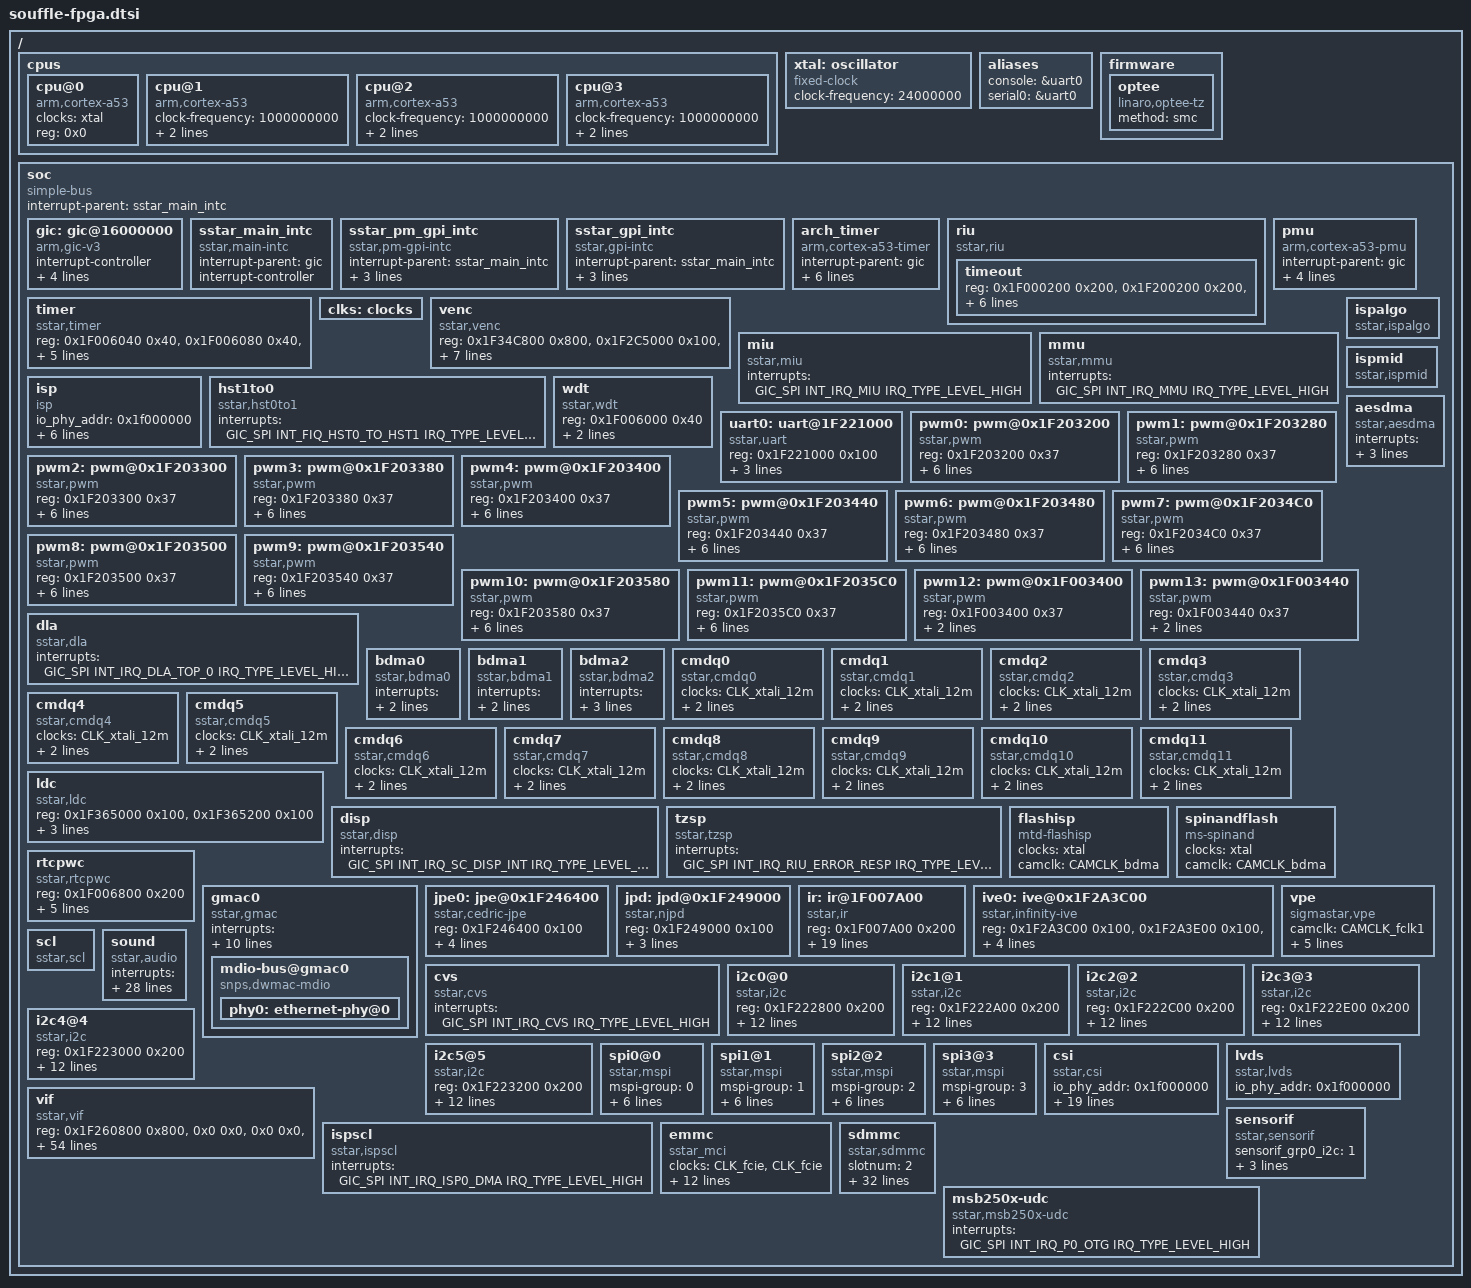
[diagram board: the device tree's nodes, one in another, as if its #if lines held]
/*
* mercury6p-fpga.dtsi- Sigmastar
*
* Copyright (c) [2019~2020] SigmaStar Technology.
*
*
* This software is licensed under the terms of the GNU General Public
* License version 2, as published by the Free Software Foundation, and
* may be copied, distributed, and modified under those terms.
*
* This program is distributed in the hope that it will be useful,
* but WITHOUT ANY WARRANTY; without even the implied warranty of
* MERCHANTABILITY or FITNESS FOR A PARTICULAR PURPOSE.  See the
* GNU General Public License version 2 for more details.
*
*/
#include "../../../../include/generated/autoconf.h"
#include "../../../../drivers/sstar/include/souffle/irqs.h"
#include "../../../../drivers/sstar/include/souffle/gpio.h"
#include <dt-bindings/interrupt-controller/irq.h>
#include <dt-bindings/interrupt-controller/arm-gic.h>
#include <dt-bindings/input/input.h>

/ {
    cpus {
        #address-cells = <1>;
        #size-cells = <0>;

        cpu@0 {
            device_type = "cpu";
            compatible = "arm,cortex-a53";
            clocks = <&xtal>;
            reg = <0x0>;
        };

#ifdef CONFIG_SMP
        cpu@1 {
            device_type = "cpu";
            compatible = "arm,cortex-a53";
            clock-frequency = <1000000000>;
            clocks = <&xtal>;
            reg = <0x1>;
        };

        cpu@2 {
            device_type = "cpu";
            compatible = "arm,cortex-a53";
            clock-frequency = <1000000000>;
            clocks = <&xtal>;
            reg = <0x2>;
        };

        cpu@3 {
            device_type = "cpu";
            compatible = "arm,cortex-a53";
            clock-frequency = <1000000000>;
            clocks = <&xtal>;
            reg = <0x3>;
        };
#endif
    };

    xtal: oscillator {
        compatible = "fixed-clock";
        #clock-cells = <0>;
        clock-frequency = <24000000>;
    };

    aliases {
        console = &uart0;
        serial0 = &uart0;
    };

#ifdef CONFIG_OPTEE
    firmware {
        optee {
            compatible = "linaro,optee-tz";
            method = "smc";
        };
    };
#endif

    soc {
        compatible = "simple-bus";
        interrupt-parent = <&sstar_main_intc>;
        #address-cells = <1>;
        #size-cells = <1>;
        ranges;

        gic: gic@16000000 {
            compatible = "arm,gic-v3";
            #interrupt-cells = <3>;
            #address-cells = <1>;
            #size-cells = <1>;
            interrupt-controller;
            interrupt-parent = <&gic>;
            redistributor-stride = <0x0 0x20000>;
            #redistributor-regions = <1>;
            reg = <0x16000000 0x20000>,
                  <0x16080000 0x80000>;
        };

        sstar_main_intc: sstar_main_intc {
            compatible = "sstar,main-intc";
            #interrupt-cells = <3>;
            #address-cells = <1>;
            #size-cells = <1>;
            interrupt-parent=<&gic>;
            interrupt-controller;
        };

        sstar_pm_gpi_intc: sstar_pm_gpi_intc {
            compatible = "sstar,pm-gpi-intc";
            #interrupt-cells = <1>;
            interrupt-parent=<&sstar_main_intc>;
            interrupt-controller;
            interrupts = <GIC_SPI INT_IRQ_PM_SLEEP IRQ_TYPE_LEVEL_HIGH>;
        };

        sstar_gpi_intc: sstar_gpi_intc {
            compatible = "sstar,gpi-intc";
            #interrupt-cells = <1>;
            interrupt-parent=<&sstar_main_intc>;
            interrupt-controller;
            interrupts = <GIC_SPI INT_IRQ_GPI_OUT IRQ_TYPE_LEVEL_HIGH>;
        };

        arch_timer {
            compatible = "arm,cortex-a53-timer", "arm,armv8-timer";
            interrupt-parent=<&gic>;
            interrupts = <GIC_PPI 13 (GIC_CPU_MASK_SIMPLE(2) | IRQ_TYPE_LEVEL_LOW)>,
                         <GIC_PPI 14 (GIC_CPU_MASK_SIMPLE(2) | IRQ_TYPE_LEVEL_LOW)>,
                         <GIC_PPI 11 (GIC_CPU_MASK_SIMPLE(2) | IRQ_TYPE_LEVEL_LOW)>,
                         <GIC_PPI 10 (GIC_CPU_MASK_SIMPLE(2) | IRQ_TYPE_LEVEL_LOW)>;
            clock-frequency = <36000000>;  /* arch_timer must use clock-frequency*/
        };

        riu {
            #address-cells = <1>;
            #size-cells = <1>;
            compatible = "sstar,riu";
            ranges;
            status = "ok";
            timeout {
                reg = <0x1F000200 0x200>, <0x1F200200 0x200>, <0x1F240200 0x200>, <0x1F2CE000 0x200>;
                interrupts= <GIC_SPI INT_FIQ_PM_XIU_TIMEOUT IRQ_TYPE_LEVEL_HIGH>, <GIC_SPI INT_FIQ_XIU_TIMEOUT IRQ_TYPE_LEVEL_HIGH>,
                            <GIC_SPI INT_FIQ_SC_XIU_TIMEOUT IRQ_TYPE_LEVEL_HIGH>, <GIC_SPI INT_FIQ_XIU_XIU_TIMEOUT IRQ_TYPE_LEVEL_HIGH>;
                //bug-on;
                status = "ok";
            };
        };

        timer {
            compatible = "sstar,timer";
            reg = <0x1F006040 0x40>, <0x1F006080 0x40>, <0x1F0060C0 0x40>;
            interrupts = <GIC_SPI INT_FIQ_TIMER_OR IRQ_TYPE_LEVEL_HIGH>, <GIC_SPI INT_FIQ_TIMER_OR IRQ_TYPE_LEVEL_HIGH>, <GIC_SPI INT_FIQ_TIMER_OR IRQ_TYPE_LEVEL_HIGH>;
            status = "ok";
        };

        pmu {
            compatible = "arm,cortex-a53-pmu";
            interrupt-parent=<&gic>;
            interrupts = <GIC_SPI 10 IRQ_TYPE_LEVEL_HIGH>,
                         <GIC_SPI 16 IRQ_TYPE_LEVEL_HIGH>,
                         <GIC_SPI 22 IRQ_TYPE_LEVEL_HIGH>,
                         <GIC_SPI 28 IRQ_TYPE_LEVEL_HIGH>;
        };

        clks: clocks{
            #address-cells = <1>;
            #size-cells = <1>;
            ranges;
        };

        venc {
            compatible = "sstar,venc";
            reg = <0x1F34C800 0x800>, <0x1F2C5000 0x100>, <0x1F203C00 0x100>, <0x1F207800 0x100>, <0x1F2C5000 0x100>;
            reg-names = "vpu-bit", "venc-brige", "hw-uart0", "hw-uart1", "venc-gp";
            interrupts = <GIC_SPI INT_IRQ_MHE_0 IRQ_TYPE_LEVEL_HIGH>;
            interrupt-parent = <&sstar_main_intc>;
            interrupt-names = "mhe-irq";
            clocks = <&CLK_vhe>, <&CLK_mfe>, <&CLK_ven_axi>,<&CLK_ven_scdn>;
            clock-names = "CKG_venc";
            status = "ok";
        };

        miu {
            compatible = "sstar,miu";
            interrupts=<GIC_SPI INT_IRQ_MIU IRQ_TYPE_LEVEL_HIGH>;
            status = "ok";
        };

        mmu {
            compatible = "sstar,mmu";
            interrupts=<GIC_SPI INT_IRQ_MMU IRQ_TYPE_LEVEL_HIGH>;
            status = "ok";
        };
        isp: isp {
            compatible = "isp";
            io_phy_addr = <0x1f000000>;
            banks = <0x1302>;
            interrupts = <GIC_SPI INT_IRQ_ISP_0 IRQ_TYPE_LEVEL_HIGH>;
            clocks = <&CLK_isp>,<&CLK_fclk1>,<&CLK_dsc_enc1>,<&CLK_dsc_dec1>;
            status = "ok";
            clock-frequency-index = <0>;
        };

        ispalgo: ispalgo {
            compatible = "sstar,ispalgo";
            status = "ok";
        };

/*
        ispscl: ispscl {
            compatible = "sstar,ispscl";
            interrupts = <GIC_SPI INT_IRQ_ISP0_DMA IRQ_TYPE_LEVEL_HIGH>;
            status = "ok";
        };
*/

        hst1to0 {
            compatible = "sstar,hst0to1";
            interrupts = <GIC_SPI INT_FIQ_HST0_TO_HST1 IRQ_TYPE_LEVEL_HIGH>;
            status = "ok";
        };

        ispmid: ispmid {
            compatible = "sstar,ispmid";
            status = "ok";
        };

        wdt {
            compatible = "sstar,wdt";
            reg = <0x1F006000 0x40>;
            interrupts=<GIC_SPI INT_FIQ_WDT IRQ_TYPE_EDGE_RISING>;
            status = "ok";
        };

        uart0: uart@1F221000 {
            compatible = "sstar,uart";
            reg = <0x1F221000 0x100>;
            interrupts= <GIC_SPI INT_IRQ_FUART_0 IRQ_TYPE_LEVEL_HIGH>;
            status = "ok";
            clocks = <&xtal>;
        };
        aesdma {
            compatible = "sstar,aesdma";
            interrupts=<GIC_SPI INT_IRQ_WADR_ERROR IRQ_TYPE_LEVEL_HIGH>;
            clocks = <&CLK_aesdma>;
#ifdef CONFIG_CAM_CLK
            camclk = <CAMCLK_aesdma>;
#endif
            status = "ok";
        };

        pwm0: pwm@0x1F203200{
            compatible = "sstar,pwm";
            reg = <0x1F203200 0x37>;
            #pwm-cells = <3>;
            channel = <0>;
            group = <0>;
            clocks = <&CLK_pwm>;
            clk-select = <0>;
            interrupts=<GIC_SPI INT_IRQ_PWM IRQ_TYPE_LEVEL_HIGH>;
            status = "ok";
        };

        pwm1: pwm@0x1F203280 {
            compatible = "sstar,pwm";
            reg = <0x1F203280 0x37>;
            #pwm-cells = <3>;
            channel = <1>;
            group = <0>;
            clocks = <&CLK_pwm>;
            clk-select = <0>;
            interrupts=<GIC_SPI INT_IRQ_PWM IRQ_TYPE_LEVEL_HIGH>;
            status = "ok";
        };

        pwm2: pwm@0x1F203300 {
            compatible = "sstar,pwm";
            reg = <0x1F203300 0x37>;
            #pwm-cells = <3>;
            channel = <2>;
            group = <0>;
            clocks = <&CLK_pwm>;
            clk-select = <0>;
            interrupts=<GIC_SPI INT_IRQ_PWM IRQ_TYPE_LEVEL_HIGH>;
            status = "ok";
        };

        pwm3: pwm@0x1F203380 {
            compatible = "sstar,pwm";
            reg = <0x1F203380 0x37>;
            #pwm-cells = <3>;
            channel = <3>;
            group = <0>;
            clocks = <&CLK_pwm>;
            clk-select = <0>;
            interrupts=<GIC_SPI INT_IRQ_PWM IRQ_TYPE_LEVEL_HIGH>;
            status = "ok";
        };

        pwm4: pwm@0x1F203400 {
            compatible = "sstar,pwm";
            reg = <0x1F203400 0x37>;
            #pwm-cells = <3>;
            channel = <4>;
            group = <1>;
            clocks = <&CLK_pwm>;
            clk-select = <0>;
            interrupts=<GIC_SPI INT_IRQ_PWM IRQ_TYPE_LEVEL_HIGH>;
            status = "ok";
        };

        pwm5: pwm@0x1F203440 {
            compatible = "sstar,pwm";
            reg = <0x1F203440 0x37>;
            #pwm-cells = <3>;
            channel = <5>;
            group = <1>;
            clocks = <&CLK_pwm>;
            clk-select = <0>;
            interrupts=<GIC_SPI INT_IRQ_PWM IRQ_TYPE_LEVEL_HIGH>;
            status = "ok";
        };

        pwm6: pwm@0x1F203480 {
            compatible = "sstar,pwm";
            reg = <0x1F203480 0x37>;
            #pwm-cells = <3>;
            channel = <6>;
            group = <1>;
            clocks = <&CLK_pwm>;
            clk-select = <0>;
            interrupts=<GIC_SPI INT_IRQ_PWM IRQ_TYPE_LEVEL_HIGH>;
            status = "ok";
        };

        pwm7: pwm@0x1F2034C0 {
            compatible = "sstar,pwm";
            reg = <0x1F2034C0 0x37>;
            #pwm-cells = <3>;
            channel = <7>;
            group = <1>;
            clocks = <&CLK_pwm>;
            clk-select = <0>;
            interrupts=<GIC_SPI INT_IRQ_PWM IRQ_TYPE_LEVEL_HIGH>;
            status = "ok";
        };

        pwm8: pwm@0x1F203500 {
            compatible = "sstar,pwm";
            reg = <0x1F203500 0x37>;
            #pwm-cells = <3>;
            channel = <8>;
            group = <2>;
            clocks = <&CLK_pwm>;
            clk-select = <0>;
            interrupts=<GIC_SPI INT_IRQ_PWM IRQ_TYPE_LEVEL_HIGH>;
            status = "ok";
        };

        pwm9: pwm@0x1F203540 {
            compatible = "sstar,pwm";
            reg = <0x1F203540 0x37>;
            #pwm-cells = <3>;
            channel = <9>;
            group = <2>;
            clocks = <&CLK_pwm>;
            clk-select = <0>;
            interrupts=<GIC_SPI INT_IRQ_PWM IRQ_TYPE_LEVEL_HIGH>;
            status = "ok";
        };

        pwm10: pwm@0x1F203580 {
            compatible = "sstar,pwm";
            reg = <0x1F203580 0x37>;
            #pwm-cells = <3>;
            channel = <10>;
            group = <2>;
            clocks = <&CLK_pwm>;
            clk-select = <0>;
            interrupts=<GIC_SPI INT_IRQ_PWM IRQ_TYPE_LEVEL_HIGH>;
            status = "ok";
        };

        pwm11: pwm@0x1F2035C0 {
            compatible = "sstar,pwm";
            reg = <0x1F2035C0 0x37>;
            #pwm-cells = <3>;
            channel = <11>;
            group = <2>;
            clocks = <&CLK_pwm>;
            clk-select = <0>;
            interrupts=<GIC_SPI INT_IRQ_PWM IRQ_TYPE_LEVEL_HIGH>;
            status = "ok";
        };

        pwm12: pwm@0x1F003400 {
            compatible = "sstar,pwm";
            reg = <0x1F003400 0x37>;
            #pwm-cells = <3>;
            channel = <12>;
            //clocks = <&CLK_pm_pwm>;
            clk-select = <0>;
            status = "ok";
        };

        pwm13: pwm@0x1F003440 {
            compatible = "sstar,pwm";
            reg = <0x1F003440 0x37>;
    #pwm-cells = <3>;
            channel = <12>;
            //clocks = <&CLK_pm_pwm>;
            clk-select = <0>;
            status = "ok";
        };


        dla {
            compatible = "sstar,dla";
            interrupts = <GIC_SPI INT_IRQ_DLA_TOP_0 IRQ_TYPE_LEVEL_HIGH>;
            status = "ok";
        };

        bdma0 {
            compatible = "sstar,bdma0";
            interrupts=<GIC_SPI INT_IRQ_BDMA_1 IRQ_TYPE_LEVEL_HIGH>;
            reg = <0x1F200400 0x100>;
            //clocks = <&CLK_bdma>;
            status = "ok";
        };

        bdma1 {
            compatible = "sstar,bdma1";
            interrupts=<GIC_SPI INT_IRQ_BDMA_2 IRQ_TYPE_LEVEL_HIGH>;
            reg = <0x1F201600 0x100>;
            //clocks = <&CLK_bdma>;
            status = "ok";
        };

        bdma2 {
            compatible = "sstar,bdma2";
            interrupts=<GIC_SPI INT_IRQ_BDMA_3 IRQ_TYPE_LEVEL_HIGH>;
            reg = <0x1F201800 0x100>;
            clocks = <&xtal>;
            status = "ok";
        };

        cmdq0 {
            compatible = "sstar,cmdq0";
            clocks = <&CLK_xtali_12m>; //for timeout tick
            interrupts=<GIC_SPI INT_IRQ_CMDQ IRQ_TYPE_LEVEL_HIGH>;
            status = "ok";
        };

        cmdq1 {
            compatible = "sstar,cmdq1";
            clocks = <&CLK_xtali_12m>; //for timeout tick
            interrupts=<GIC_SPI INT_IRQ_CMDQ IRQ_TYPE_LEVEL_HIGH>;
            status = "ok";
        };

        cmdq2 {
            compatible = "sstar,cmdq2";
            clocks = <&CLK_xtali_12m>; //for timeout tick
            interrupts=<GIC_SPI INT_IRQ_CMDQ IRQ_TYPE_LEVEL_HIGH>;
            status = "ok";
        };

        cmdq3 {
            compatible = "sstar,cmdq3";
            clocks = <&CLK_xtali_12m>; //for timeout tick
            interrupts=<GIC_SPI INT_IRQ_CMDQ IRQ_TYPE_LEVEL_HIGH>;
            status = "ok";
        };

        cmdq4 {
            compatible = "sstar,cmdq4";
            clocks = <&CLK_xtali_12m>; //for timeout tick
            interrupts=<GIC_SPI INT_IRQ_CMDQ_1 IRQ_TYPE_LEVEL_HIGH>;
            status = "ok";
        };

        cmdq5 {
            compatible = "sstar,cmdq5";
            clocks = <&CLK_xtali_12m>; //for timeout tick
            interrupts=<GIC_SPI INT_IRQ_CMDQ_1 IRQ_TYPE_LEVEL_HIGH>;
            status = "ok";
        };

        cmdq6 {
            compatible = "sstar,cmdq6";
            clocks = <&CLK_xtali_12m>; //for timeout tick
            interrupts=<GIC_SPI INT_IRQ_CMDQ_1 IRQ_TYPE_LEVEL_HIGH>;
            status = "ok";
        };
        cmdq7 {
            compatible = "sstar,cmdq7";
            clocks = <&CLK_xtali_12m>; //for timeout tick
            interrupts=<GIC_SPI INT_IRQ_CMDQ_1 IRQ_TYPE_LEVEL_HIGH>;
            status = "ok";
        };

        cmdq8 {
            compatible = "sstar,cmdq8";
            clocks = <&CLK_xtali_12m>; //for timeout tick
            interrupts=<GIC_SPI INT_IRQ_CMDQ_ISP_0 IRQ_TYPE_LEVEL_HIGH>;
            status = "ok";
        };

        cmdq9 {
            compatible = "sstar,cmdq9";
            clocks = <&CLK_xtali_12m>; //for timeout tick
            interrupts=<GIC_SPI INT_IRQ_CMDQ_ISP_0 IRQ_TYPE_LEVEL_HIGH>;
            status = "ok";
        };

        cmdq10 {
            compatible = "sstar,cmdq10";
            clocks = <&CLK_xtali_12m>; //for timeout tick
            interrupts=<GIC_SPI INT_IRQ_CMDQ_ISP_0 IRQ_TYPE_LEVEL_HIGH>;
            status = "ok";
        };

        cmdq11 {
            compatible = "sstar,cmdq11";
            clocks = <&CLK_xtali_12m>; //for timeout tick
            interrupts=<GIC_SPI INT_IRQ_CMDQ_ISP_0 IRQ_TYPE_LEVEL_HIGH>;
            status = "ok";
        };
        ldc: ldc {
            compatible = "sstar,ldc";
            reg = <0x1F365000 0x100>, <0x1F365200 0x100>;
            interrupts=<GIC_SPI INT_IRQ_LDC IRQ_TYPE_LEVEL_HIGH>;
            clocks = <&CLK_ldcfeye>;
            status = "ok";
        };
        disp: disp {
            compatible = "sstar,disp";
            status = "ok";
            //clocks = <&CLK_fclk1>, <&CLK_disp_pixel_0>;
            interrupts = <GIC_SPI INT_IRQ_SC_DISP_INT IRQ_TYPE_LEVEL_HIGH>;
            //Reg = <0x1F224000 0x200>;
        };
#ifdef CONFIG_OPTEE
        tzsp {
            compatible = "sstar,tzsp";
            interrupts=<GIC_SPI INT_IRQ_RIU_ERROR_RESP IRQ_TYPE_LEVEL_HIGH>;
            status = "ok";
        };
#endif
        flashisp {
            compatible = "mtd-flashisp";
            clocks = <&xtal>;
#ifdef CONFIG_CAM_CLK
            camclk = <CAMCLK_bdma>;
#endif
            status = "ok";
        };

        spinandflash {
            compatible = "ms-spinand";
            clocks = <&xtal>;
#ifdef CONFIG_CAM_CLK
            camclk = <CAMCLK_bdma>;
#endif
            status = "ok";
        };

        rtcpwc {
            compatible = "sstar,rtcpwc";
            reg = <0x1F006800 0x200>;
            interrupts=<GIC_SPI INT_IRQ_DIG_TOP IRQ_TYPE_LEVEL_HIGH>;
            alarm-enable;
            //alarm-init-on;
            //io0-hiz;
            //io2-wos = <1>;           //0:CMPHL 1:CMPHL 2:CMPL 3:CMPH
            //io2-wos-v = <0x2 0x3>;   //<vl vh> 0<vl<8 0<vh<8
            //io3-pu;
            //offset-count = <100>;
            //offset-nagative;
            //iso-auto-regen;
            /*
             * io4 control source selection
             * io0/io1/io2/io3 ctrl bit0
             * alarm ctrl           bit1
             * sw ctrl              bit2
             * support the combination of above ways
             */
            io4-enable = <7>;
            /*
             * io5 control source selection
             * io4 ctrl    bit0
             * alarm ctrl  bit1
             * sw ctrl     bit2
             * support the combination of above ways
             */
            io5-enable = <7>;   // for demo board,use 3,default hight
            //io5-no-poweroff;    // io5 keep when excute 'poweroff' use for wakeup pm51
            status = "ok";
        };

        gmac0 {
            compatible = "sstar,gmac","snps,dwmac-5.10a";
            interrupts = <GIC_SPI INT_IRQ_NET_GP_TOP0 IRQ_TYPE_LEVEL_HIGH>;
            interrupt-names = "macirq";
            reg = <0x1F32A000 0x1300>;
            gmac-id = <0>;
            gmac-bank = <0x1950>, <0x1951>, <0x1952>, <0x1953>, <0x1954>, <0x1955>, <0x1956>, <0x1957>;
            clocks = <&CLK_gmac0_gmii>;
            clock-names = "gmac-clk";
            snps,tso;
            phy-handle = <&phy0>;
            phy-mode = "rmii";
            max-speed = <10>;
            //snps,txpbl = <16>;
            //snps,rxpbl = <16>;
            //snps,aal;
            status = "ok";
            mdio-bus@gmac0 {
                compatible = "snps,dwmac-mdio";
                phy0: ethernet-phy@0 {
                };
            };
        };
        jpe0: jpe@0x1F246400 {
            compatible = "sstar,cedric-jpe";
            reg = <0x1F246400 0x100>;
            interrupts = <GIC_SPI INT_IRQ_JPE IRQ_TYPE_LEVEL_HIGH>;
            clocks = <&CLK_jpe>;
            clock-names = "CKG_jpe";
            interrupt-names = "jpe-irq0";
            clk-select = <0>; // 0: 480M  1: 432MHz  2: 384MHz  3: 320MHz 4: 288MHz 5:216MHz
            status = "ok";
        };
        jpd: jpd@0x1F249000 {
            compatible = "sstar,njpd";
            reg = <0x1F249000 0x100>;
            interrupts = <GIC_SPI INT_IRQ_JPD IRQ_TYPE_LEVEL_HIGH>;
            clocks = <&CLK_jpd>; //jpd
            clock-names = "CKG_jpd";
            status = "ok";
        };

        ir: ir@1F007A00 {
            compatible = "sstar,ir";
            reg = <0x1F007A00 0x200>;
            clocks = <&CLK_ir>;
            interrupts = <GIC_SPI INT_FIQ_IR IRQ_TYPE_LEVEL_HIGH>,<GIC_SPI INT_FIQ_IR_RC IRQ_TYPE_LEVEL_HIGH>;
            group =<0>;
            /*
             * decode mode selection
             * FULL   1
             * RAW    2
             * RC5    3
             * SW     4  only support at linux
             */
            mode = <1>;
            //protocol = enum rc_proto
            protocol = <9>;
            vendor-id = <0x000E>;
            product-id = <0x3412>;
            //header-code = <header_code0  header_code1>
            header-code   = <0x00 0xFF>;
            //rc-map-table = <command_code  input_key_code>
            rc-map-table =
                <0x00A8 KEY_POWER>,       // POWER KEY
                <0x00C0 KEY_F5>,          // VOICE KEY
                <0x00DD KEY_GREEN>,       // SOURCE KEY
                <0x0044 KEY_F19>,         // SETTING KEY
                <0x00CA KEY_UP>,          // UP KEY
                <0x00D2 KEY_DOWN>,        // DOWN KEY
                <0x0099 KEY_LEFT>,        // LEFT KEY
                <0x00C1 KEY_RIGHT>,       // RIGHT KEY
                <0x00CE KEY_ENTER>,       // OK KEY
                <0x00CB KEY_BACK>,        // BACK KEY
                <0x0087 KEY_HOMEPAGE>,    // HOME KEY
                <0x0097 KEY_COMPOSE>,     // MENU KEY
                <0x0041 KEY_PLAYPAUSE>,   // FOCUS KEY
                <0x000F KEY_F16>,         // FOCUS INCREASE KEY
                <0x0060 KEY_F20>,         // FOCUS DECREASE KEY
                <0x0090 KEY_VOLUMEUP>,    // VOLUMEUP KEY
                <0x0098 KEY_VOLUMEDOWN>,  // VOLUMEDOWN KEY
                <0x00D1 KEY_MUTE>;        // MUTE KEY
            status = "ok";
        };

        ive0: ive@0x1F2A3C00 {
            compatible = "sstar,infinity-ive";
            reg = <0x1F2A3C00 0x100>,<0x1F2A3E00 0x100>,<0x1F2A4000 0x100>,<0x1F2A4200 0x100>;
            interrupts = <GIC_SPI INT_IRQ_IVE IRQ_TYPE_LEVEL_HIGH>;
            clocks = <&CLK_ive>;
            status = "ok";
        };

        vpe: vpe {
            compatible = "sigmastar,vpe";
            status = "ok";
            #ifdef CONFIG_CAM_CLK
            camclk = <CAMCLK_fclk1>;
            #else
            clocks = <&CLK_fclk1>;
            #endif
            interrupts = <GIC_SPI INT_IRQ_SC_TOP IRQ_TYPE_LEVEL_HIGH>, <GIC_SPI INT_IRQ_SC_TOP_INT IRQ_TYPE_LEVEL_HIGH>, <GIC_SPI INT_IRQ_SC_TOP_3 IRQ_TYPE_LEVEL_HIGH>, <GIC_SPI INT_IRQ_SC_TOP_4 IRQ_TYPE_LEVEL_HIGH>;
        };

        scl: scl {
            compatible = "sstar,scl";
            status = "ok";
        };

        cvs {
            compatible = "sstar,cvs";
            interrupts = <GIC_SPI INT_IRQ_CVS IRQ_TYPE_LEVEL_HIGH>;
            interrupt-names = "cvs_irq";
            status = "ok";
        };

        sound {
            compatible = "sstar,audio";
            interrupts=<GIC_SPI INT_IRQ_BACH IRQ_TYPE_LEVEL_HIGH>;
            //amp-pad = <PAD_GPIO2 1 PAD_GPIO2 1>;
            clocks = <&CLK_au_sys_384>;
#ifdef CONFIG_CAM_CLK
            camclk = <CAMCLK_bach>;
#endif
            // padmux
            digmic-padmux = <5>;
            i2s-trx-shared-padmux = <0>; //for 4-wired mode panmux
            i2s-tx-padmux = <6>; //6-wired mode
            i2s-rx-padmux = <7>; //6-wired mode
            i2s-mck-padmux = <7>;

            keep-i2s-clk = <0>;
            i2s-pcm = <0>;
            i2s-rx-mode = <0>;

            // I2S RX TDM
            i2s-rx0-tdm-ws-pgm = <0>;   // 0: OFF  1: ON
            i2s-rx0-tdm-ws-width = <0>; // value: 0~31 (width = value + 1)
            i2s-rx0-tdm-ws-inv = <0>;   // 0: normal  1: inverse WCK
            i2s-rx0-tdm-bck-inv = <0>;  // 0: normal  1: inverse BCK
            i2s-rx0-tdm-ch-swap = <0 0 0 0>; // 0: OFF  1: ON

            // I2S TX TDM
            i2s-tx0-tdm-ws-pgm = <0>;   // 0: OFF  1: ON
            i2s-tx0-tdm-ws-width = <0>; // value: 0~31 (width = value + 1)
            i2s-tx0-tdm-ws-inv = <0>;   // 0: normal  1: inverse WCK
            i2s-tx0-tdm-bck-inv = <0>;  // 0: normal  1: inverse BCK
            i2s-tx0-tdm-ch-swap = <0 0 0 0>; // 0: OFF  1: ON
            i2s-tx0-tdm-active-slot = <0xFFFF>; // value: 0x00 ~ 0xFF (bit0->slot0, bit1->slot1, ... )

            // dmic bck mode
            dmic-bck-mode-8k = <3>;    //2.4M
            dmic-bck-mode-16k = <6>;   //2.4M
            dmic-bck-mode-32k = <9>;   //4.8M
            dmic-bck-mode-48k = <11>;  //4.8M

            // hpf default level
            hpf-adc1-dmic2ch-level = <1 0xf>;//1:use this level 0: not use this level; 0xf:hpf level 0~0xf
            hpf-dmic4ch-level      = <1 0x0>;

            status = "ok";
        };

        i2c0@0{
            compatible = "sstar,i2c";
            reg = <0x1F222800 0x200>;
            #address-cells = <1>;
            #size-cells = <0>;
            interrupts = <GIC_SPI INT_IRQ_MIIC IRQ_TYPE_LEVEL_HIGH>;
            clocks = <&CLK_miic0>;
            i2c-group = <0>;
            i2c-en-dma = <1>;
            i2c-speed = <200000>;
            i2c-t-hd = <0>;//if u want set tHD,set here not 0,tHD = (i2c-t-hd / i2c-srcclk)S
            i2c-t-su = <0>;//if u want set tSU,set here not 0,tSU = (i2c-t-su / i2c-srcclk)S
            i2c-t-start = <0>;
            i2c-t-stop = <0>;
            i2c-push-pull = <1>;//set 1 enable push-pull output,set 0 open drain
            i2c-oen-cnt   = <1>;
            status = "ok";
         };


        i2c1@1{
            compatible = "sstar,i2c";
            reg = <0x1F222A00 0x200>;
            #address-cells = <1>;
            #size-cells = <0>;
            interrupts = <GIC_SPI INT_IRQ_MIIC IRQ_TYPE_LEVEL_HIGH>;
            clocks = <&CLK_miic1>;
            i2c-group = <1>;
            i2c-en-dma = <1>;
            i2c-speed = <200000>;
            i2c-t-hd = <0>;//if u want set tHD,set here not 0,tHD = (i2c-t-hd / i2c-srcclk)S
            i2c-t-su = <0>;//if u want set tSU,set here not 0,tSU = (i2c-t-su / i2c-srcclk)S
            i2c-t-start = <0>;
            i2c-t-stop = <0>;
            i2c-push-pull = <1>;//set 1 enable push-pull output,set 0 open drain
            i2c-oen-cnt   = <1>;
            status = "ok";
        };

        i2c2@2{
            compatible = "sstar,i2c";
            reg = <0x1F222C00 0x200>;
            #address-cells = <1>;
            #size-cells = <0>;
            interrupts = <GIC_SPI INT_IRQ_MIIC IRQ_TYPE_LEVEL_HIGH>;
            clocks = <&CLK_miic2>;
            i2c-group = <2>;
            i2c-en-dma = <1>;
            i2c-speed = <200000>;
            i2c-t-hd = <0>;//if u want set tHD,set here not 0,tHD = (i2c-t-hd / i2c-srcclk)S
            i2c-t-su = <0>;//if u want set tSU,set here not 0,tSU = (i2c-t-su / i2c-srcclk)S
            i2c-t-start = <0>;
            i2c-t-stop = <0>;
            i2c-push-pull = <1>;//set 1 enable push-pull output,set 0 open drain
            i2c-oen-cnt   = <1>;
            status = "ok";
        };

        i2c3@3{
            compatible = "sstar,i2c";
            reg = <0x1F222E00 0x200>;
            #address-cells = <1>;
            #size-cells = <0>;
            interrupts = <GIC_SPI INT_IRQ_MIIC IRQ_TYPE_LEVEL_HIGH>;
            clocks = <&CLK_miic3>;
            i2c-group = <3>;
            i2c-en-dma = <1>;
            i2c-speed = <200000>;
            i2c-t-hd = <0>;//if u want set tHD,set here not 0,tHD = (i2c-t-hd / i2c-srcclk)S
            i2c-t-su = <0>;//if u want set tSU,set here not 0,tSU = (i2c-t-su / i2c-srcclk)S
            i2c-t-start = <0>;
            i2c-t-stop = <0>;
            i2c-push-pull = <1>;//set 1 enable push-pull output,set 0 open drain
            i2c-oen-cnt   = <1>;
            status = "ok";
        };

        i2c4@4{
            compatible = "sstar,i2c";
            reg = <0x1F223000 0x200>;
            #address-cells = <1>;
            #size-cells = <0>;
            interrupts = <GIC_SPI INT_IRQ_MIIC IRQ_TYPE_LEVEL_HIGH>;
            clocks = <&CLK_miic3>;
            i2c-group = <4>;
            i2c-en-dma = <1>;
            i2c-speed = <200000>;
            i2c-t-hd = <0>;//if u want set tHD,set here not 0,tHD = (i2c-t-hd / i2c-srcclk)S
            i2c-t-su = <0>;//if u want set tSU,set here not 0,tSU = (i2c-t-su / i2c-srcclk)S
            i2c-t-start = <0>;
            i2c-t-stop = <0>;
            i2c-push-pull = <1>;//set 1 enable push-pull output,set 0 open drain
            i2c-oen-cnt   = <1>;
            status = "ok";
        };

        i2c5@5{
            compatible = "sstar,i2c";
            reg = <0x1F223200 0x200>;
            #address-cells = <1>;
            #size-cells = <0>;
            interrupts = <GIC_SPI INT_IRQ_MIIC IRQ_TYPE_LEVEL_HIGH>;
            clocks = <&CLK_miic3>;
            i2c-group = <5>;
            i2c-en-dma = <1>;
            i2c-speed = <200000>;
            i2c-t-hd = <0>;//if u want set tHD,set here not 0,tHD = (i2c-t-hd / i2c-srcclk)S
            i2c-t-su = <0>;//if u want set tSU,set here not 0,tSU = (i2c-t-su / i2c-srcclk)S
            i2c-t-start = <0>;
            i2c-t-stop = <0>;
            i2c-push-pull = <1>;//set 1 enable push-pull output,set 0 open drain
            i2c-oen-cnt   = <1>;
            status = "ok";
        };

        spi0@0{
            compatible = "sstar,mspi";
            mspi-group = <0>;
#ifdef CONFIG_CAM_CLK
            camclk = <CAMCLK_mspi0>;
#else
            clocks = <&CLK_mspi0>;
#endif
            reg = <0x1F222000 0x200>;
            interrupts = <GIC_SPI INT_IRQ_MSPI_0 IRQ_TYPE_LEVEL_HIGH>;
            use-dma = <0>;
            cs-num = <1>;
            //cs-ext = <PAD_UNKNOWN>;
            //4to3-mode;
            //clk-out-mode = <27000000>;
            status = "ok";
        };

        spi1@1{
            compatible = "sstar,mspi";
            mspi-group = <1>;
#ifdef CONFIG_CAM_CLK
            camclk = <CAMCLK_mspi1>;
#else
            clocks = <&CLK_mspi0>;
#endif
            reg = <0x1F222200 0x200>;
            interrupts = <GIC_SPI INT_IRQ_MSPI_1 IRQ_TYPE_LEVEL_HIGH>;
            use-dma = <0>;
            cs-num = <1>;
            //cs-ext = <PAD_UNKNOWN>;
            //4to3-mode;
            //clk-out-mode = <27000000>;
            status = "ok";
        };

        spi2@2{
            compatible = "sstar,mspi";
            mspi-group = <2>;
#ifdef CONFIG_CAM_CLK
            camclk = <CAMCLK_mspi2>;
#else
            clocks = <&CLK_mspi0>;
#endif
            reg = <0x1F222400 0x200>;
            interrupts = <GIC_SPI INT_IRQ_MSPI_2 IRQ_TYPE_LEVEL_HIGH>;
            use-dma = <0>;
            cs-num = <1>;
            //cs-ext = <PAD_UNKNOWN>;
            //4to3-mode;
            //clk-out-mode = <27000000>;
            status = "ok";
        };

        spi3@3{
            compatible = "sstar,mspi";
            mspi-group = <3>;
#ifdef CONFIG_CAM_CLK
            camclk = <CAMCLK_mspi3>;
#else
            clocks = <&CLK_mspi0>;
#endif
            reg = <0x1F222600 0x200>;
            interrupts = <GIC_SPI INT_IRQ_MSPI_3 IRQ_TYPE_LEVEL_HIGH>;
            use-dma = <0>;
            cs-num = <1>;
            //cs-ext = <PAD_UNKNOWN>;
            //4to3-mode;
            //clk-out-mode = <27000000>;
            status = "ok";
        };

    csi: csi {
            compatible = "sstar,csi";
            io_phy_addr = <0x1f000000>;
            banks = <0x1544>,<0x1545>,<0x1546>,<0x153C>,<0x153D>,<0x153E>,<0x1540>,<0x1541>,<0x154E>,<0x1538>,<0x153A>,<0x153B>;
            atop_banks = <0x1548>,<0x1549>,<0x154A>;
            clkgen_banks = <0x1038>;
            interrupts=  <GIC_SPI INT_IRQ_MIPI_CSI2 IRQ_TYPE_LEVEL_HIGH>;
            //clocks = <&CLK_csi_mac_lptx_top_i_m00>,<&CLK_csi_mac_top_i_m00>,<&CLK_ns_top_i_m00>,<&CLK_csi_mac_lptx_top_i_m1>,<&CLK_csi_mac_top_i_m1>,<&CLK_ns_top_i_m1>,<&CLK_csi_mac_lptx_top_i_m01>,<&CLK_csi_mac_top_i_m01>,<&CLK_ns_top_i_m01>;
            //clocks = <&CLK_csi_mac_lptx_top_i_m00>,<&CLK_csi_mac_top_i_m00>,<&CLK_ns_top_i_m00>,<&CLK_csi_mac_lptx_top_i_m01>,<&CLK_csi_mac_top_i_m01>,<&CLK_ns_top_i_m01>;
            status = "ok";
            /* Config max lane number */
            csi_sr0_lane_num = <4>;
            csi_sr1_lane_num = <4>;
            csi_sr2_lane_num = <2>;
            csi_sr3_lane_num = <2>;
            /* Config lane selection */
            csi_sr0_lane_select = <2 4 3 1 0>;
            csi_sr1_lane_select = <2 4 3 1 0>;
            csi_sr2_lane_select = <2 1 0>;
            csi_sr3_lane_select = <2 1 0>;
            /* Config lane P/N swap */
            csi_sr0_lane_pn_swap = <0 0 0 0 0>;
            csi_sr1_lane_pn_swap = <0 0 0 0 0>;
            csi_sr2_lane_pn_swap = <0 0 0>;
            csi_sr3_lane_pn_swap = <0 0 0>;
        };

    lvds: lvds {
            compatible = "sstar,lvds";
            io_phy_addr = <0x1f000000>;
            //Attention: Sub_LVDS use the same hwirq line with the MIPI_CSI
            status = "ok";
        };

    vif: vif {
            compatible = "sstar,vif";
            status = "ok";
            reg = <0x1F260800 0x800>, <0x0 0x0>, <0x0 0x0>, <0x0 0x0>, <0x0 0x0>, <0x1F207C 0x200>, <0x1F207800 0x200>, <0x1F227400 0x200>, <0x1F207000 0x200>, <0x1F000000 0x400000>, <0x1F203C00 0x200>, <0x1F260600 0x200>;
            //clocks = <&CLK_sr00_mclk>,<&CLK_sr1_mclk>,<&CLK_sr01_mclk>;
            interrupts = <GIC_SPI INT_IRQ_ISP0_VIF IRQ_TYPE_LEVEL_HIGH>;
            /* Config sensor 0 pad mux */
            vif_sr0_mipi_mode         = <1>;
            vif_sr0_mipi_ctrl_mode    = <1>;
            vif_sr0_mipi_rst_mode     = <1>;
            vif_sr0_mipi_pdn_mode     = <1>;
            vif_sr0_mipi_mclk_mode    = <1>;
            vif_sr0_par_mode          = <1>;
            vif_sr0_par_ctrl_mode     = <1>;
            vif_sr0_par_rst_mode      = <1>;
            vif_sr0_par_pdn_mode      = <1>;
            vif_sr0_par_mclk_mode     = <1>;
            vif_sr0_bt656_mode        = <1>;
            vif_sr0_bt656_ctrl_mode   = <1>;
            vif_sr0_bt656_rst_mode    = <1>;
            vif_sr0_bt656_pdn_mode    = <1>;
            vif_sr0_bt656_mclk_mode   = <1>;
            vif_sr0_bt1120_mode       = <1>;
            vif_sr0_bt1120_ctrl_mode  = <1>;
            vif_sr0_bt1120_rst_mode   = <1>;
            vif_sr0_bt1120_pdn_mode   = <1>;
            vif_sr0_bt1120_mclk_mode  = <1>;

            /* Config sensor 2 pad mux */
            vif_sr1_mipi_mode         = <1>;
            vif_sr1_mipi_ctrl_mode    = <1>;
            vif_sr1_mipi_rst_mode     = <1>;
            vif_sr1_mipi_pdn_mode     = <1>;
            vif_sr1_mipi_mclk_mode    = <1>;
            vif_sr1_par_mode          = <1>;
            vif_sr1_par_rst_mode      = <1>;
            vif_sr1_par_ctrl_mode     = <1>;
            vif_sr1_par_pdn_mode      = <1>;
            vif_sr1_par_mclk_mode     = <1>;
            vif_sr1_bt656_mode        = <8>;
            vif_sr1_bt656_ctrl_mode   = <1>;
            vif_sr1_bt656_rst_mode    = <1>;
            vif_sr1_bt656_pdn_mode    = <1>;
            vif_sr1_bt656_mclk_mode   = <1>;

            /* Config sensor 1 pad mux */
            vif_sr2_mipi_mode         = <1>;
            vif_sr2_mipi_ctrl_mode    = <1>;
            vif_sr2_mipi_rst_mode     = <1>;
            vif_sr2_mipi_pdn_mode     = <1>;
            vif_sr2_mipi_mclk_mode    = <1>;

            /* Config sensor 3 pad mux */
            vif_sr3_mipi_mode         = <1>;
            vif_sr3_mipi_ctrl_mode    = <2>;
            vif_sr3_mipi_rst_mode     = <1>;
            vif_sr3_mipi_pdn_mode     = <1>;
            vif_sr3_mipi_mclk_mode    = <1>;

            /* Config mclk 37.125MHz supported */
            vif_sr0_mclk_37p125 = <1>;
            vif_sr1_mclk_37p125 = <1>;
            vif_sr2_mclk_37p125 = <1>;
        };

        ispscl: ispscl {
            compatible = "sstar,ispscl";
            interrupts = <GIC_SPI INT_IRQ_ISP0_DMA IRQ_TYPE_LEVEL_HIGH>;
            status = "ok";
        };

        sensorif: sensorif {
            compatible = "sstar,sensorif";
            status = "ok";
            sensorif_grp0_i2c = <1>;
            sensorif_grp1_i2c = <1>;
            sensorif_grp2_i2c = <1>;
            sensorif_grp3_i2c = <1>;
        };

        emmc {
            compatible = "sstar_mci";
            clocks =<&CLK_fcie>, <&CLK_fcie>; //, <&CLK_sdio2>;
            clock-names = "clk_fcie0", "clk_fcie1", "clk_fcie2","clk_fcie3";
            interrupts = <GIC_SPI INT_IRQ_SD IRQ_TYPE_LEVEL_HIGH>,
                         <GIC_SPI INT_IRQ_FCIE IRQ_TYPE_LEVEL_HIGH>;

            slot-num = <1>;
            adma-mode = <1>,<1>,<1>;
            ip-select = <1>,<0>,<2>;
            pad-select = <0>,<0>,<0>;
            bus-width = <8>,<4>,<4>;
            max-clks = <48000000>,<48000000>,<48000000>;
            clk-driving  = <0>,<0>,<0>;
            cmd-driving  = <0>,<0>,<0>;
            data-driving = <0>,<0>,<0>;
            status = "ok";
        };

        sdmmc {
            compatible = "sstar,sdmmc";

            slotnum = <2>;
            revcdz = <0>;

            slot-ip-orders = <0>,<1>,<2>;
            slot-pad-orders = <0>,<0>,<0>;
            slot-max-clks = <48000000>,<48000000>,<48000000>;
            slot-intcdzs = <1>,<1>,<0>;
            slot-support-sd30 = <0>,<0>,<0>;
            slot-fakecdzs = <0>,<0>,<0>;
            slot-cdzs-pad = <PAD_SD0_CDZ>,<PAD_SD0_GPIO0>,<PAD_EMMC_RSTN>;
            slot-pwr-pad = <PAD_SD0_GPIO0>,<PAD_SD0_GPIO0>,<PAD_SD0_GPIO0>;
            slot-pwr-off-delay = <30>,<30>,<30>;
            slot-pwr-on-delay = <1>,<1>,<1>;
            slot-removable = <1>,<1>,<1>;
            slot-sdio-use = <0>,<0>,<0>;
            slot-sdio-use-1bit = <0>,<0>,<0>;
            slot-sdio-dis-intr = <0>,<0>,<0>;
            slot-en-clk-phase = <0>,<0>,<0>; //0/1
            slot-tx-clk-phase = <0>,<0>,<0>; //0-3
            slot-rx-clk-phase = <0>,<0>,<0>; //0-3
            slot-clk-driving = <0>,<0>,<0>;
            slot-cmd-driving = <0>,<0>,<0>;
            slot-data-driving = <0>,<0>,<0>;

            interrupts-extended = <&sstar_main_intc GIC_SPI INT_IRQ_SD IRQ_TYPE_LEVEL_HIGH>,
                                  <&sstar_main_intc GIC_SPI INT_IRQ_SDIO IRQ_TYPE_LEVEL_HIGH>,
                                  <&sstar_main_intc GIC_SPI INT_IRQ_FCIE IRQ_TYPE_LEVEL_HIGH>,

                                  <&sstar_main_intc GIC_SPI INT_FIQ_SD_CDZ_0 IRQ_TYPE_LEVEL_HIGH>,
                                  <&sstar_main_intc GIC_SPI INT_FIQ_SD_CDZ_2 IRQ_TYPE_LEVEL_HIGH>,
                                  <&sstar_main_intc GIC_SPI INT_FIQ_SD_CDZ_1 IRQ_TYPE_LEVEL_HIGH>;
            interrupt-names = "mie0_irq", "mie1_irq", "mie2_irq", "cdz_slot0_irq", "cdz_slot1_irq", "cdz_slot2_irq";
            clocks = <&CLK_sd>,<&CLK_fcie>,
                     <&CLK_sd>,<&CLK_fcie>,
                     <&CLK_sd>,<&CLK_fcie>;
            status = "ok";
        };

        msb250x-udc {
            compatible = "sstar,msb250x-udc";
            interrupts = <GIC_SPI INT_IRQ_P0_OTG IRQ_TYPE_LEVEL_HIGH>;
            status = "ok";
        };
    };
};

&clks {
    #include "../../../../drivers/sstar/include/souffle/reg_clks.h"
    #include "souffle-clks.dtsi"
};
